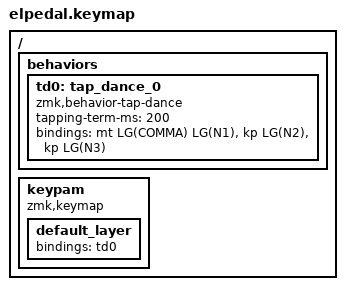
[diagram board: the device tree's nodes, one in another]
#include <behaviors.dtsi>
#include <dt-bindings/zmk/keys.h>
#include <dt-bindings/zmk/bt.h>

/ {
    behaviors {
        td0: tap_dance_0 {
            compatible = "zmk,behavior-tap-dance";
            #binding-cells = <0>;
            tapping-term-ms = <200>;
            bindings = <&mt LG(COMMA) LG(N1)>, <&kp LG(N2)>, <&kp LG(N3)>;
        };
    };

    keypam {
        compatible = "zmk,keymap";

        default_layer {
            bindings = <
                &td0
            >;
        };
    };
};
